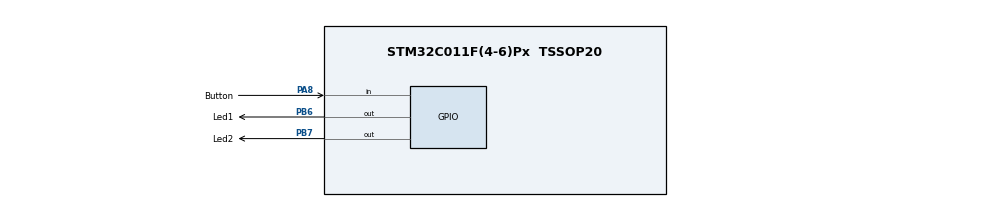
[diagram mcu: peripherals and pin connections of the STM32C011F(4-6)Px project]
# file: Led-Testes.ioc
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Mcu.Family=STM32C0
Mcu.Name=STM32C011F(4-6)Px
Mcu.Package=TSSOP20
PA10\ [PA12].Signal=USART1_RX
PA13.Mode=Serial_Wire
PA13.Signal=DEBUG_SWDIO
PA14-BOOT0.Mode=Serial_Wire
PA14-BOOT0.Signal=DEBUG_SWCLK
PA8.GPIO_Label=Button
PA8.GPIO_PuPd=GPIO_PULLUP
PA8.Signal=GPIO_Input
PA9\ [PA11].Signal=USART1_TX
PB6.GPIO_Label=Led1
PB6.Signal=GPIO_Output
PB7.GPIO_Label=Led2
PB7.Signal=GPIO_Output
ProjectManager.HeapSize=0x200
ProjectManager.StackSize=0x400
ProjectManager.TargetToolchain=STM32CubeIDE
RCC.ADCFreq_Value=48000000
RCC.AHBFreq_Value=48000000
RCC.CortexFreq_Value=48000000
RCC.EXTERNAL_CLOCK_VALUE=12288000
RCC.HCLKFreq_Value=48000000
RCC.HSE_VALUE=8000000
RCC.HSISYSCLKDivider=RCC_HSI_DIV1
RCC.HSI_VALUE=48000000
RCC.LSE_VALUE=32768
RCC.SYSCLKFreq_VALUE=48000000
VP_SYS_VS_PINREMAP.Mode=PINREMAP
VP_SYS_VS_PINREMAP_10_12.Mode=PINREMAP_10_12
board=custom

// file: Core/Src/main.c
/* USER CODE BEGIN Header */
/**
  ******************************************************************************
  * @file           : main.c
  * @brief          : Main program body
  ******************************************************************************
  * @attention
  *
  * Copyright (c) 2026 STMicroelectronics.
  * All rights reserved.
  *
  * This software is licensed under terms that can be found in the LICENSE file
  * in the root directory of this software component.
  * If no LICENSE file comes with this software, it is provided AS-IS.
  *
  ******************************************************************************
  */
/* USER CODE END Header */
#include "main.h"
#include <stdio.h>
/* USER CODE BEGIN Includes */
#include "led.h"

/* USER CODE END Includes */

void SystemClock_Config(void);
static void MX_GPIO_Init(void);

int main(void)
{

  /* MCU Configuration--------------------------------------------------------*/

  /* Reset of all peripherals, Initializes the Flash interface and the Systick. */
  HAL_Init();

  /* Configure the system clock */
  SystemClock_Config();

  /* Initialize all configured peripherals */
  MX_GPIO_Init();
  /* USER CODE BEGIN 2 */
  LedOn(1);
  LedOff(2);
  /* USER CODE END 2 */
  /* Infinite loop */
  while (1)
  {
	  PushButton(8);
	  HAL_Delay(500);
  }
}

void SystemClock_Config(void)
{
  RCC_OscInitTypeDef RCC_OscInitStruct = {0};
  RCC_ClkInitTypeDef RCC_ClkInitStruct = {0};

  __HAL_FLASH_SET_LATENCY(FLASH_LATENCY_1);

  /** Initializes the RCC Oscillators according to the specified parameters
  * in the RCC_OscInitTypeDef structure.
  */
  RCC_OscInitStruct.OscillatorType = RCC_OSCILLATORTYPE_HSI;
  RCC_OscInitStruct.HSIState = RCC_HSI_ON;
  RCC_OscInitStruct.HSIDiv = RCC_HSI_DIV1;
  RCC_OscInitStruct.HSICalibrationValue = RCC_HSICALIBRATION_DEFAULT;
  if (HAL_RCC_OscConfig(&RCC_OscInitStruct) != HAL_OK)
  {
    Error_Handler();
  }

  /** Initializes the CPU, AHB and APB buses clocks
  */
  RCC_ClkInitStruct.ClockType = RCC_CLOCKTYPE_HCLK|RCC_CLOCKTYPE_SYSCLK
                              |RCC_CLOCKTYPE_PCLK1;
  RCC_ClkInitStruct.SYSCLKSource = RCC_SYSCLKSOURCE_HSI;
  RCC_ClkInitStruct.SYSCLKDivider = RCC_SYSCLK_DIV1;
  RCC_ClkInitStruct.AHBCLKDivider = RCC_HCLK_DIV1;
  RCC_ClkInitStruct.APB1CLKDivider = RCC_APB1_DIV1;

  if (HAL_RCC_ClockConfig(&RCC_ClkInitStruct, FLASH_LATENCY_1) != HAL_OK)
  {
    Error_Handler();
  }
}

static void MX_GPIO_Init(void)
{
  GPIO_InitTypeDef GPIO_InitStruct = {0};

  /* GPIO Ports Clock Enable */
  __HAL_RCC_GPIOB_CLK_ENABLE();
  __HAL_RCC_GPIOA_CLK_ENABLE();

  /*Configure GPIO pin Output Level */
  HAL_GPIO_WritePin(GPIOB, Led2_Pin|Led1_Pin, GPIO_PIN_RESET);

  /*Configure GPIO pins : Led2_Pin Led1_Pin */
  GPIO_InitStruct.Pin = Led2_Pin|Led1_Pin;
  GPIO_InitStruct.Mode = GPIO_MODE_OUTPUT_PP;
  GPIO_InitStruct.Pull = GPIO_NOPULL;
  GPIO_InitStruct.Speed = GPIO_SPEED_FREQ_LOW;
  HAL_GPIO_Init(GPIOB, &GPIO_InitStruct);

  /*Configure GPIO pin : Button_Pin */
  GPIO_InitStruct.Pin = Button_Pin;
  GPIO_InitStruct.Mode = GPIO_MODE_INPUT;
  GPIO_InitStruct.Pull = GPIO_PULLUP;
  HAL_GPIO_Init(Button_GPIO_Port, &GPIO_InitStruct);

  /*Configure GPIO pins : PA9 PA10 */
  GPIO_InitStruct.Pin = GPIO_PIN_9|GPIO_PIN_10;
  GPIO_InitStruct.Mode = GPIO_MODE_AF_PP;
  GPIO_InitStruct.Pull = GPIO_NOPULL;
  GPIO_InitStruct.Speed = GPIO_SPEED_FREQ_LOW;
  GPIO_InitStruct.Alternate = GPIO_AF1_USART1;
  HAL_GPIO_Init(GPIOA, &GPIO_InitStruct);

}

void Error_Handler(void)
{
  __disable_irq();
  while (1)
  {
  }
}
